AUTOSAR XML (schema 4-2-2)
package /CDD_CORE0
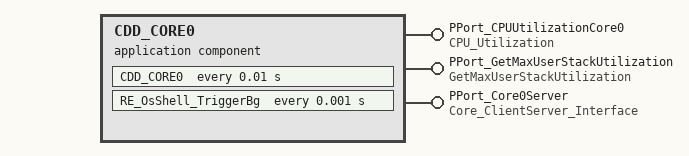
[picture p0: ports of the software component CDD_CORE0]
  application sw component type CDD_CORE0
    provide port PPort_CPUUtilizationCore0: provided-interface=CPU_Utilization
    provide port PPort_GetMaxUserStackUtilization: provided-interface=GetMaxUserStackUtilization
    provide port PPort_Core0Server: server-com-spec{operation=Core_ClientServer, queue-length=3}, provided-interface=Core_ClientServer_Interface
    behavior SwcInternalBehavior
      timing event TimingEvent_1: start-on-event=CDD_CORE0, period=0.01
      timing event TimingEvent_2: start-on-event=RE_OsShell_TriggerBg, period=0.001
      operation invoked event OperationInvokedEvent_0: start-on-event=GetMaxUserStackUtilization_Core0, operation=PPort_GetMaxUserStackUtilization.GetMaxUserStackUtilization
      operation invoked event OperationInvokedEvent_1: start-on-event=CPUUtilizationCore0, operation=PPort_CPUUtilizationCore0.CPU_Utilization
      operation invoked event OperationInvokedEvent_2: start-on-event=RE_CORE0_SERVER, operation=PPort_Core0Server.Core_ClientServer
      5 x runnable:
        CPUUtilizationCore0: symbol=CPUUtilizationCore0_func
        CDD_CORE0: symbol=CDD_CORE0_func
        RE_OsShell_TriggerBg: symbol=RE_OsShell_TriggerBg_func
        GetMaxUserStackUtilization_Core0: symbol=GetMaxUserStackUtilization_Core0_func
        RE_CORE0_SERVER: symbol=RE_CORE0_SERVER_func
